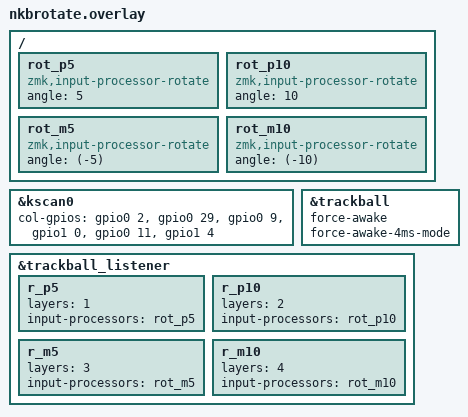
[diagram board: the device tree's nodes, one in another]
/* Rotation test: cursor rotated by a per-layer angle; key1/key2 cycle angle.
   Layers: L0=0deg L1=+5 L2=+10 L3=-5 L4=-10. */
#include "nice_kb.dtsi"
#include <input/processors.dtsi>

&kscan0 {
    col-gpios
        = <&gpio0  2 (GPIO_ACTIVE_HIGH | GPIO_PULL_DOWN)>
        , <&gpio0 29 (GPIO_ACTIVE_HIGH | GPIO_PULL_DOWN)>
        , <&gpio0  9 (GPIO_ACTIVE_HIGH | GPIO_PULL_DOWN)>
        , <&gpio1  0 (GPIO_ACTIVE_HIGH | GPIO_PULL_DOWN)>
        , <&gpio0 11 (GPIO_ACTIVE_HIGH | GPIO_PULL_DOWN)>
        , <&gpio1  4 (GPIO_ACTIVE_HIGH | GPIO_PULL_DOWN)>
        ;
};

&trackball {
    force-awake;
    force-awake-4ms-mode;
};

/ {
    rot_p5:  rot_p5  { compatible = "zmk,input-processor-rotate"; #input-processor-cells = <0>; angle = <5>;    };
    rot_p10: rot_p10 { compatible = "zmk,input-processor-rotate"; #input-processor-cells = <0>; angle = <10>;   };
    rot_m5:  rot_m5  { compatible = "zmk,input-processor-rotate"; #input-processor-cells = <0>; angle = <(-5)>;  };
    rot_m10: rot_m10 { compatible = "zmk,input-processor-rotate"; #input-processor-cells = <0>; angle = <(-10)>; };
};

/* L0 = no rotation (0deg). Other layers apply their angle to the cursor. */
&trackball_listener {
    r_p5  { layers = <1>; input-processors = <&rot_p5>;  };
    r_p10 { layers = <2>; input-processors = <&rot_p10>; };
    r_m5  { layers = <3>; input-processors = <&rot_m5>;  };
    r_m10 { layers = <4>; input-processors = <&rot_m10>; };
};
